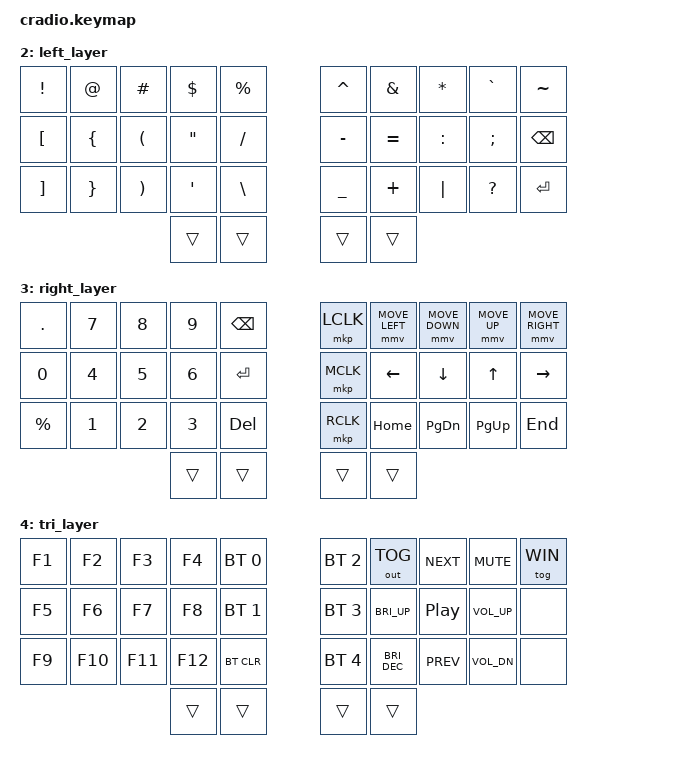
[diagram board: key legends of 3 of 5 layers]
// Copyright (c) 2022 The ZMK Contributors
// SPDX-License-Identifier: MIT

#include <behaviors.dtsi>
#include <dt-bindings/zmk/keys.h>
#include <dt-bindings/zmk/bt.h>
#include <dt-bindings/zmk/outputs.h>
#include <dt-bindings/zmk/mouse.h>

// Home row mods macro
#define HRML(k2,k3,k4) &ht LALT k2  &ht LCTRL k3  &ht LGUI k4
#define HRMR(k1,k2,k3) &ht RGUI k1  &ht RCTRL k2  &ht RALT k3
#define WHRML(k2,k3,k4) &ht LALT k2  &ht LGUI k3  &ht LCTRL k4
#define WHRMR(k1,k2,k3) &ht RCTRL k1  &ht RGUI k2  &ht RALT k3

#define MAC 0
#define WIN 1
#define LEF 2
#define RIG 3
#define TRI 4

#define U_MOUSE_MOVE_MAX 1400                     /* <--- New max speed setting (default: 600) */
#undef MOVE_UP
#undef MOVE_DOWN
#undef MOVE_LEFT
#undef MOVE_RIGHT

#define MOVE_UP MOVE_VERT(-U_MOUSE_MOVE_MAX)
#define MOVE_DOWN MOVE_VERT(U_MOUSE_MOVE_MAX)
#define MOVE_LEFT MOVE_HOR(-U_MOUSE_MOVE_MAX)
#define MOVE_RIGHT MOVE_HOR(U_MOUSE_MOVE_MAX)    

&mmv {
    time-to-max-speed-ms = <400>;             /* <--- How long time until max speed is reached (default: 500) */
};

#define U_MOUSE_SCROLL_MAX 30                    /* <--- New max speed setting (default: 10) */
#undef SCROLL_UP
#undef SCROLL_DOWN
#undef SCROLL_LEFT
#undef SCROLL_RIGHT

#define SCROLL_UP SCROLL_VERT(U_MOUSE_SCROLL_MAX)
#define SCROLL_DOWN SCROLL_VERT(-U_MOUSE_SCROLL_MAX)
#define SCROLL_LEFT SCROLL_HOR(-U_MOUSE_SCROLL_MAX)
#define SCROLL_RIGHT SCROLL_HOR(U_MOUSE_SCROLL_MAX)

&mwh {
  time-to-max-speed-ms = <500>;                 /* <--- How long time until max speed is reached */
};

&sk {
    release-after-ms = <2000>;
    quick-release;
    /delete-property/ ignore-modifiers;
};

/ {
    behaviors {
        ht: hold_tap {
            compatible = "zmk,behavior-hold-tap";
            label = "THUMBROW_MODS";
            #binding-cells = <2>;
            flavor = "tap-preferred";
            tapping-term-ms = <220>;
            quick-tap-ms = <150>;
            global-quick-tap;
            bindings = <&kp>, <&kp>;
        };
    };  
    
    combos {
        compatible = "zmk,combos";
        combo_esc {
            timeout-ms = <50>;
            key-positions = <0 1>;
            bindings = <&kp ESC>;
        };

        combo_copyw {
                timeout-ms = <50>;
                key-positions = <21 22>;
                bindings = <&kp LC(C)>;
                layers = <1>;
        };
       
        combo_pastew {
                timeout-ms = <50>;
                key-positions = <22 23>;
                bindings = <&kp LC(V)>;
                layers = <1>;
        };
       
        combo_undow {
                timeout-ms = <50>;
                key-positions = <20 24>;
                bindings = <&kp LC(Z)>;
                layers = <1>;
        };

        combo_copym {
                timeout-ms = <50>;
                key-positions = <21 22>;
                bindings = <&kp LG(C)>;
                layers = <0>;
        };
       
        combo_pastem {
                timeout-ms = <50>;
                key-positions = <22 23>;
                bindings = <&kp LG(V)>;
                layers = <0>;
        };

        combo_undom {
                timeout-ms = <50>;
                key-positions = <20 24>;
                bindings = <&kp LG(Z)>;
                layers = <0>;
        };
    
        combo_backspace {
                timeout-ms = <50>;
                key-positions = <8 9>;
                bindings = <&kp BACKSPACE>;
                layers = <0 1 3>;
        };

        combo_enter {
                timeout-ms = <50>;
                key-positions = <31 32>;
                bindings = <&kp ENTER>;
        };
    };

    conditional_layers {
        compatible = "zmk,conditional-layers";
        tri_layer {
            if-layers = <RIG LEF>;
            then-layer = <TRI>;
        };
    };



    keymap {
        compatible = "zmk,keymap";
        mac_layer {
            bindings = <
        //╭──────────┬──────────┬──────────┬──────────┬──────────╮   ╭──────────┬──────────┬──────────┬──────────┬──────────╮
        //│  Q       │  W       │  E       │  R       │  T       │   │  Y       │  U       │  I       │  O       │  P       │
            &kp Q      &kp W      &kp E      &kp R      &kp T          &kp Y      &kp U      &kp I      &kp O      &kp P
        //├──────────┼──────────┼──────────┼──────────┼──────────┤   ├──────────┼──────────┼──────────┼──────────┼──────────┤
        //│  A       │  S       │  D       │  F       │  G       │   │  H       │  J       │  K       │  L       │  BACKDEL │
            &kp A     HRML(S,         D,         F)     &kp G          &kp H      HRMR(J,        K,           L)   &kp BACKSPACE
        //├──────────┼──────────┼──────────┼──────────┼──────────┤   ├──────────┼──────────┼──────────┼──────────┼──────────┤
        //│  Z       │  X       │  C       │  V       │  B       │   │  N       │  M       │ , <      │ . >      │  ENTER   │
            &kp Z      &kp X      &kp C      &kp V      &kp B          &kp N      &kp M      &kp COMMA  &kp DOT    &kp ENTER
        //╰──────────┴──────────┴──────────┼──────────┼──────────┤   ├──────────┼──────────┼──────────┴──────────┴──────────╯
                                           &lt LEF TAB  &kp LSFT       &kp SPACE  &lt RIG TAB
        //                                 ╰──────────┴──────────╯   ╰──────────┴──────────╯
            >;
        };

        windows_layer {
            bindings = <
        //╭──────────┬──────────┬──────────┬──────────┬──────────╮   ╭──────────┬──────────┬──────────┬──────────┬──────────╮
        //│  Q       │  W       │  E       │  R       │  T       │   │  Y       │  U       │  I       │  O       │  P       │
            &kp Q      &kp W      &kp E      &kp R      &kp T          &kp Y      &kp U      &kp I      &kp O      &kp P
        //├──────────┼──────────┼──────────┼──────────┼──────────┤   ├──────────┼──────────┼──────────┼──────────┼──────────┤
        //│  A       │  S       │  D       │  F       │  G       │   │  H       │  J       │  K       │  L       │  BACKDEL │
            &kp A    WHRML(S,         D,         F)     &kp G          &kp H      WHRMR(J,        K,         L)   &kp BACKSPACE
        //├──────────┼──────────┼──────────┼──────────┼──────────┤   ├──────────┼──────────┼──────────┼──────────┼──────────┤
        //│  Z       │  X       │  C       │  V       │  B       │   │  N       │  M       │ , <      │ . >      │ ENTER    │
            &kp Z      &kp X      &kp C      &kp V      &kp B          &kp N      &kp M      &kp COMMA  &kp DOT    &kp ENTER
        //╰──────────┴──────────┴──────────┼──────────┼──────────┤   ├──────────┼──────────┼──────────┴──────────┴──────────╯
                                           &lt LEF TAB  &kp LSFT       &kp SPACE  &lt RIG TAB
        //                                 ╰──────────┴──────────╯   ╰──────────┴──────────╯
            >;
        };


         left_layer {
            bindings = <
        //╭──────────┬──────────┬──────────┬──────────┬──────────╮   ╭──────────┬──────────┬──────────┬──────────┬──────────╮
        //│  !       │  @       │  #       │  $       │  %       │   │  ^       │  &       │  *       │  `       │  ~       │
            &kp EXCL   &kp AT     &kp HASH   &kp DLLR   &kp PRCNT      &kp CARET  &kp AMPS   &kp ASTRK  &kp GRAVE   &kp TILDE
        //├──────────┼──────────┼──────────┼──────────┼──────────┤   ├──────────┼──────────┼──────────┼──────────┼──────────┤
        //│  [       │  {       │  (       │    "     │   /          │    -     │  =       │     :    │  ;       │ BACKDEL  |
             &kp LBKT   &kp LBRC   &kp LPAR  &kp DQT     &kp FSLH      &kp MINUS  &kp EQUAL  &kp COLON   &kp SEMI  &kp BACKSPACE 
        //├──────────┼──────────┼──────────┼──────────┼──────────┤   ├──────────┼──────────┼──────────┼──────────┼──────────┤
        //│  ]       │  }       │  )       │  '       │    \         │     _    │  +       │  │       │   ?      │  ENTER   |
            &kp RBKT   &kp RBRC   &kp RPAR   &kp SQT    &kp BSLH      &kp UNDER  &kp PLUS   &kp PIPE   &kp QMARK    &kp ENTER
        //╰──────────┴──────────┴──────────┼──────────┼──────────┤   ├──────────┼──────────┼──────────┴──────────┴──────────╯
                                             &trans      &trans         &trans     &trans
        //                                 ╰──────────┴──────────╯   ╰──────────┴──────────╯
            >;
        };

        right_layer {
            bindings = <
        //╭──────────────────┬────────────────┬─────────────────┬──────────────────┬──────────────╮    ╭─────────────┬─────────────┬────────────────┬─────────────┬─────────────╮
        //│         .        │   7            │       8         │    9             │  BACKSPACE   │    │    M B3     │    M LEFT   │    M DOWN      │   M UP      │  M RIGHT    │   
                 &kp DOT          &kp N7          &kp N8            &kp N9          &kp BACKSPACE        &mkp LCLK     &mmv MOVE_LEFT   &mmv MOVE_DOWN  &mmv MOVE_UP  &mmv MOVE_RIGHT   
        //├──────────────────┬────────────────┬─────────────────┬──────────────────┬──────────────│    │─────────────┬─────────────┬────────────────┬─────────────┬─────────────┤
        //│       0          │  4             │       5         │   6              │      ENTER   │    │     M B1    |     LEFT    |   DOWN         │     UP      │      RIGHT  │ 
                 &kp N0          &kp N4               &kp N5          &kp N6          &kp ENTER         &mkp MCLK       &kp LEFT       &kp DOWN         &kp UP        &kp RIGHT          
        //├──────────────────┬────────────────┬────────────────┬───────────────────┬──────────────│    │─────────────┬─────────────┬────────────────┬─────────────┬─────────────┤
        //│          %       │  1             │       2        │   3               │    DELETE    │    │    M B3     |   HOME      │   PD DOWN      │     PG UP   │     END     │  
                 &kp PRCNT       &kp N1               &kp N2          &kp N3           &kp DEL             &mkp RCLK     &kp HOME      &kp PG_DN         &kp PG_UP      &kp END 
        //├──────────────────┴────────────────┴────────────────┴───────────────────┴──────────────│    │─────────────┴─────────────┴────────────────┴─────────────┴─────────────╯
                                                                    &trans              &trans             &trans           &trans
        //                                                      ╰───────────────────┴──────────────╯    ╰─────────────┴─────────────╯                                                             
            >;
        };


        tri_layer {
            bindings = <
        //╭──────────┬──────────┬──────────┬───────────┬────────────╮   ╭────────────┬────────────┬──────────┬───────────┬──────────╮
        //│  F1      │  F2      │  F3      │  F4       │ PROFILE 0  │   │ PROFILE 2  │ TOGGLEOUT  │ NEXTSONG │ VOL MUTE  │  WINDOWS │
            &kp F1     &kp F2     &kp F3     &kp F4     &bt BT_SEL 0     &bt BT_SEL 2 &out OUT_TOG &kp C_NEXT  &kp C_MUTE   &tog WIN
        //├──────────┼──────────┼──────────┼───────────┼────────────┤   ├────────────┼────────────┼──────────┼───────────┼──────────┤
        //│  F5      │  F6      │  F7      │  F8       │ PROFILE 1  │   │ PROFILE 3  │ INC BRIGHT │PAUSEMUSIC│ VOL UP    │   NONE   │
            &kp F5     &kp F6     &kp F7     &kp F8     &bt BT_SEL 1     &bt BT_SEL 3 &kp C_BRI_UP &kp C_PP   &kp C_VOL_UP &none
        //├──────────┼──────────┼──────────┼───────────┼────────────┤   ├────────────┼────────────┼──────────┼───────────┼──────────┤
        //│  F9      │  F10     │  F11     │  F12      │  CLEAR BT  │   │ PROFILE 4  │ DEC BRIGHT │ PREVSONG | VOL DOWN  │    NONE  │  
            &kp F9     &kp F10    &kp F11    &kp F12     &bt BT_CLR      &bt BT_SEL 4  &kp C_BRI_DEC &kp C_PREV &kp C_VOL_DN &none
        //╰──────────┴──────────┴──────────┼───────────┼────────────┤   ├────────────┼────────────┼──────────┴───────────┴──────────╯
                                                &trans     &trans         &trans     &trans
        //                                  ╰───────────┴──────────╯   ╰──────────┴────────────╯
            >;
        };
    };
};
